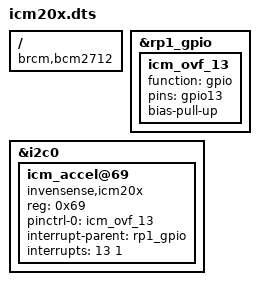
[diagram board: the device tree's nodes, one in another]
/dts-v1/;
/plugin/;
/ {
	compatible = "brcm,bcm2712";
	fragment@0 {
		target = <&rp1_gpio>;
		__overlay__ {
			icm_ovf_13: icm_ovf_13 {
				function = "gpio";
				pins = "gpio13";
				bias-pull-up;
			};
		};
	};

	fragment@1 {
		target = <&i2c0>;
		__overlay__ {
			#address-cells = <1>;
			#size-cells = <0>;

			icm_accel@69 {
				compatible = "invensense,icm20x";
				reg = <0x69>;

				pinctrl-names = "default";
				pinctrl-0 = <&icm_ovf_13>;

				interrupt-parent = <&rp1_gpio>;
				interrupts = <13 1>;

				status = "okay";
			};
		};
	};

};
